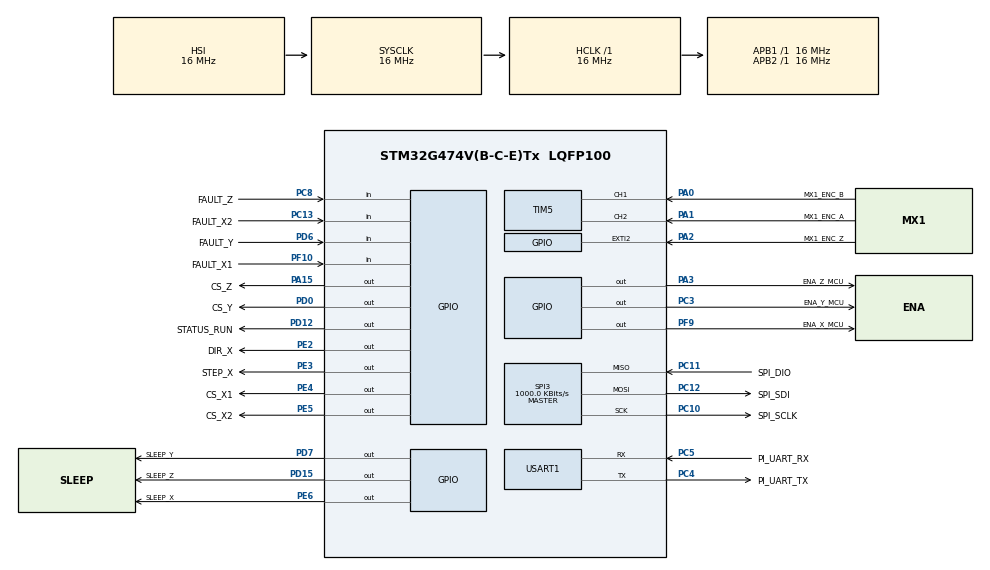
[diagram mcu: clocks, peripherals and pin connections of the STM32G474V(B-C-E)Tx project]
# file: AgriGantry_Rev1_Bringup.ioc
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Mcu.Family=STM32G4
Mcu.Name=STM32G474V(B-C-E)Tx
Mcu.Package=LQFP100
NVIC.EXTI2_IRQn=true\:0\:0\:false\:false\:true\:true\:true\:true
NVIC.PriorityGroup=NVIC_PRIORITYGROUP_4
PA0.GPIO_Label=MX1_ENC_B
PA0.Signal=S_TIM5_CH1
PA1.GPIO_Label=MX1_ENC_A
PA1.Signal=S_TIM5_CH2
PA13.Mode=Serial_Wire
PA13.Signal=SYS_JTMS-SWDIO
PA14.Mode=Serial_Wire
PA14.Signal=SYS_JTCK-SWCLK
PA15.GPIO_Label=CS_Z
PA15.PinState=GPIO_PIN_SET
PA15.Signal=GPIO_Output
PA2.GPIO_Label=MX1_ENC_Z
PA2.Signal=GPXTI2
PA3.GPIO_Label=ENA_Z_MCU
PA3.Signal=GPIO_Output
PC10.GPIO_Label=SPI_SCLK
PC10.Mode=Full_Duplex_Master
PC10.Signal=SPI3_SCK
PC11.GPIO_Label=SPI_DIO
PC11.Mode=Full_Duplex_Master
PC11.Signal=SPI3_MISO
PC12.GPIO_Label=SPI_SDI
PC12.Mode=Full_Duplex_Master
PC12.Signal=SPI3_MOSI
PC13.GPIO_Label=FAULT_X2
PC13.Signal=GPIO_Input
PC3.GPIO_Label=ENA_Y_MCU
PC3.Signal=GPIO_Output
PC4.GPIO_Label=PI_UART_TX
PC4.Mode=Asynchronous
PC4.Signal=USART1_TX
PC5.GPIO_Label=PI_UART_RX
PC5.Mode=Asynchronous
PC5.Signal=USART1_RX
PC8.GPIO_Label=FAULT_Z
PC8.Signal=GPIO_Input
PD0.GPIO_Label=CS_Y
PD0.PinState=GPIO_PIN_SET
PD0.Signal=GPIO_Output
PD12.GPIO_Label=STATUS_RUN
PD12.Signal=GPIO_Output
PD15.GPIO_Label=SLEEP_Z
PD15.Signal=GPIO_Output
PD6.GPIO_Label=FAULT_Y
PD6.Signal=GPIO_Input
PD7.GPIO_Label=SLEEP_Y
PD7.Signal=GPIO_Output
PE2.GPIO_Label=DIR_X
PE2.Signal=GPIO_Output
PE3.GPIO_Label=STEP_X
PE3.Signal=GPIO_Output
PE4.GPIO_Label=CS_X1
PE4.PinState=GPIO_PIN_SET
PE4.Signal=GPIO_Output
PE5.GPIO_Label=CS_X2
PE5.PinState=GPIO_PIN_SET
PE5.Signal=GPIO_Output
PE6.GPIO_Label=SLEEP_X
PE6.Signal=GPIO_Output
PF10.GPIO_Label=FAULT_X1
PF10.Signal=GPIO_Input
PF9.GPIO_Label=ENA_X_MCU
PF9.Signal=GPIO_Output
ProjectManager.HeapSize=0x200
ProjectManager.StackSize=0x400
ProjectManager.TargetToolchain=CMake
RCC.AHBFreq_Value=16000000
RCC.APB1Freq_Value=16000000
RCC.APB1TimFreq_Value=16000000
RCC.APB2Freq_Value=16000000
RCC.APB2TimFreq_Value=16000000
RCC.CortexFreq_Value=16000000
RCC.EXTERNAL_CLOCK_VALUE=12288000
RCC.HCLKFreq_Value=16000000
RCC.HSE_VALUE=16000000
RCC.HSI48_VALUE=48000000
RCC.HSI_VALUE=16000000
RCC.LSE_VALUE=32768
RCC.SYSCLKFreq_VALUE=16000000
RCC.USBFreq_Value=64000000
RCC.VCOOutputFreq_Value=128000000
SH.S_TIM5_CH1.0=TIM5_CH1,Encoder_Interface
SH.S_TIM5_CH2.0=TIM5_CH2,Encoder_Interface
SPI3.BaudRatePrescaler=SPI_BAUDRATEPRESCALER_16
SPI3.CLKPhase=SPI_PHASE_2EDGE
SPI3.CalculateBaudRate=1000.0 KBits/s
SPI3.DataSize=SPI_DATASIZE_8BIT
SPI3.Direction=SPI_DIRECTION_2LINES
SPI3.Mode=SPI_MODE_MASTER
SPI3.VirtualType=VM_MASTER
TIM5.EncoderMode=TIM_ENCODERMODE_TI12
USART1.VirtualMode-Asynchronous=VM_ASYNC
VP_SYS_VS_DBSignals.Mode=DisableDeadBatterySignals
board=custom

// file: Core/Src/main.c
/* USER CODE BEGIN Header */
/**
  ******************************************************************************
  * @file           : main.c
  * @brief          : Main program body
  ******************************************************************************
  * @attention
  *
  * Copyright (c) 2026 STMicroelectronics.
  * All rights reserved.
  *
  * This software is licensed under terms that can be found in the LICENSE file
  * in the root directory of this software component.
  * If no LICENSE file comes with this software, it is provided AS-IS.
  *
  ******************************************************************************
  */
/* USER CODE END Header */
#include "main.h"
#include "spi.h"
#include "tim.h"
#include "usart.h"
#include "gpio.h"

/* USER CODE BEGIN Includes */

#include "pi_uart_diag.h"

/* USER CODE END Includes */

void SystemClock_Config(void);

int main(void)
{

  /* MCU Configuration--------------------------------------------------------*/

  /* Reset of all peripherals, Initializes the Flash interface and the Systick. */
  HAL_Init();

  /* Configure the system clock */
  SystemClock_Config();

  /* Initialize all configured peripherals */
  MX_GPIO_Init();
  MX_SPI3_Init();
  MX_TIM5_Init();
  MX_USART1_UART_Init();
  /* USER CODE BEGIN 2 */

  PiUart_Init();

  /* USER CODE END 2 */

  /* Infinite loop */
  while (1)
  {

    /* USER CODE BEGIN 3 */
    PiUart_Poll();
  }
  /* USER CODE END 3 */
}

void SystemClock_Config(void)
{
  RCC_OscInitTypeDef RCC_OscInitStruct = {0};
  RCC_ClkInitTypeDef RCC_ClkInitStruct = {0};

  /** Configure the main internal regulator output voltage
  */
  HAL_PWREx_ControlVoltageScaling(PWR_REGULATOR_VOLTAGE_SCALE1);

  /** Initializes the RCC Oscillators according to the specified parameters
  * in the RCC_OscInitTypeDef structure.
  */
  RCC_OscInitStruct.OscillatorType = RCC_OSCILLATORTYPE_HSI;
  RCC_OscInitStruct.HSIState = RCC_HSI_ON;
  RCC_OscInitStruct.HSICalibrationValue = RCC_HSICALIBRATION_DEFAULT;
  RCC_OscInitStruct.PLL.PLLState = RCC_PLL_NONE;
  if (HAL_RCC_OscConfig(&RCC_OscInitStruct) != HAL_OK)
  {
    Error_Handler();
  }

  /** Initializes the CPU, AHB and APB buses clocks
  */
  RCC_ClkInitStruct.ClockType = RCC_CLOCKTYPE_HCLK|RCC_CLOCKTYPE_SYSCLK
                              |RCC_CLOCKTYPE_PCLK1|RCC_CLOCKTYPE_PCLK2;
  RCC_ClkInitStruct.SYSCLKSource = RCC_SYSCLKSOURCE_HSI;
  RCC_ClkInitStruct.AHBCLKDivider = RCC_SYSCLK_DIV1;
  RCC_ClkInitStruct.APB1CLKDivider = RCC_HCLK_DIV1;
  RCC_ClkInitStruct.APB2CLKDivider = RCC_HCLK_DIV1;

  if (HAL_RCC_ClockConfig(&RCC_ClkInitStruct, FLASH_LATENCY_0) != HAL_OK)
  {
    Error_Handler();
  }
}

void Error_Handler(void)
{
  __disable_irq();
  while (1)
  {
  }
}
